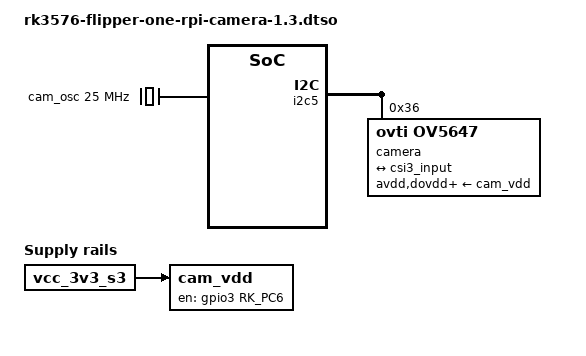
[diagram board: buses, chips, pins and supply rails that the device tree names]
// SPDX-License-Identifier: (GPL-2.0+ OR MIT)
/*
 * Device tree overlay for the Raspberry Pi Camera rev. 1.3 attached to the CSI
 * port of the Flipper One
 */

/dts-v1/;
/plugin/;

#include <dt-bindings/gpio/gpio.h>
#include <dt-bindings/pinctrl/rockchip.h>

&{/} {
	/*
	 * The camera module is self-clocked by an on-board 25 MHz oscillator;
	 * the SoC CAM_CLK2 output is not connected on this module.
	 */
	cam_osc: cam-oscillator {
		compatible = "fixed-clock";
		#clock-cells = <0>;
		clock-frequency = <25000000>;
		clock-output-names = "cam_osc";
	};

	/*
	 * GPIO3_C6 enables the module's on-board LDOs (analog/digital-IO/
	 * digital-core). The sensor's own power-down pin is tied to 1V8 on
	 * the module and is not driven by the SoC, so this line is modelled
	 * as the module power-enable regulator rather than as pwdn-gpios.
	 */
	cam_vdd: regulator-cam-vdd {
		compatible = "regulator-fixed";
		regulator-name = "cam_vdd";
		gpio = <&gpio3 RK_PC6 GPIO_ACTIVE_HIGH>;
		enable-active-high;
		startup-delay-us = <1000>;
		pinctrl-names = "default";
		pinctrl-0 = <&cam_pdn>;
		vin-supply = <&vcc_3v3_s3>;
	};
};

&csi3_in {
	csi3_input: endpoint {
		data-lanes = <1 2>;
		remote-endpoint = <&camera_out>;
	};
};

&i2c5 {
	#address-cells = <1>;
	#size-cells = <0>;

	camera@36 {
		compatible = "ovti,ov5647";
		reg = <0x36>;
		clocks = <&cam_osc>;
		avdd-supply = <&cam_vdd>;
		dovdd-supply = <&cam_vdd>;
		dvdd-supply = <&cam_vdd>;

		port {
			camera_out: endpoint {
				data-lanes = <1 2>;
				remote-endpoint = <&csi3_input>;
			};
		};
	};
};
